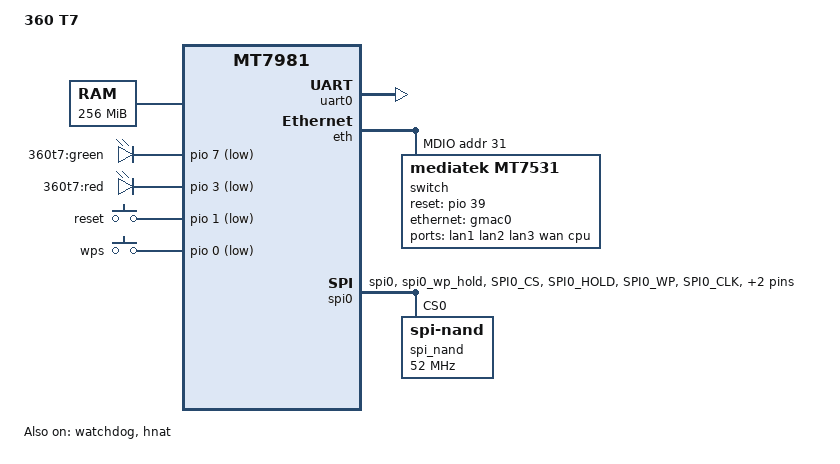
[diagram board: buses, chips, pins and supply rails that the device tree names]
/dts-v1/;
#include "mt7981.dtsi"

/ {
	model = "360 T7";
	compatible = "360,t7", "mediatek,mt7981";

	aliases {
		led-boot = &red_led;
		led-failsafe = &red_led;
		led-running = &green_led;
		led-upgrade = &green_led;
	};
	
 

	chosen {
		bootargs = "console=ttyS0,115200n1 loglevel=8  \
				earlycon=uart8250,mmio32,0x11002000";
	};

	memory {
		reg = <0 0x40000000 0 0x10000000>;
	};

	leds {
		compatible = "gpio-leds";

		green_led: green {
			label = "360t7:green";
			gpios = <&pio 7 GPIO_ACTIVE_LOW>;
		};

		red_led: red {
			label = "360t7:red";
			gpios = <&pio 3 GPIO_ACTIVE_LOW>;
		};
	};

	gpio-keys {
		compatible = "gpio-keys";
			reset {
				label = "reset";
				linux,code = <KEY_RESTART>;
				gpios = <&pio 1 GPIO_ACTIVE_LOW>;
			};

			wps {
				label = "wps";
				linux,code = <KEY_WPS_BUTTON>;
				gpios = <&pio 0 GPIO_ACTIVE_LOW>;
			};
	};

};

&uart0 {
	status = "okay";
};

&watchdog {
	status = "okay";
};


&eth {
        status = "okay";

        gmac0: mac@0 {
                compatible = "mediatek,eth-mac";
                reg = <0>;
                phy-mode = "2500base-x";

                fixed-link {
                        speed = <2500>;
                        full-duplex;
                        pause;
                };
        };

        gmac1: mac@1 {
		compatible = "mediatek,eth-mac";
		reg = <1>;
		phy-mode = "2500base-x";

		fixed-link {
			speed = <2500>;
			full-duplex;
			pause;
		};
	};

	mdio: mdio-bus {
		#address-cells = <1>;
		#size-cells = <0>;

		switch@0 {
			compatible = "mediatek,mt7531";
			reg = <31>;
			reset-gpios = <&pio 39 0>;

			ports {
				#address-cells = <1>;
				#size-cells = <0>;

				port@0 {
					reg = <0>;
					label = "lan1";
				};

				port@1 {
					reg = <1>;
					label = "lan2";
				};

				port@2 {
					reg = <2>;
					label = "lan3";
				};

				port@3 {
					reg = <3>;
					label = "wan";
				};

				port@6 {
					reg = <6>;
					label = "cpu";
					ethernet = <&gmac0>;
					phy-mode = "2500base-x";

					fixed-link {
						speed = <2500>;
						full-duplex;
						pause;
					};
				};
			};
		};
	};
};

&hnat {
	mtketh-wan = "eth1";
	mtketh-lan = "lan";
	mtketh-ppd = "eth1";
	mtketh-max-gmac = <2>;
	status = "okay";
};

&spi0 {
	pinctrl-names = "default";
	pinctrl-0 = <&spi0_flash_pins>;
	status = "okay";

	spi_nand: spi_nand@0 {
		#address-cells = <1>;
		#size-cells = <1>;
		compatible = "spi-nand";
		reg = <0>;
		spi-max-frequency = <52000000>;
		spi-tx-bus-width = <4>;
		spi-rx-bus-width = <4>;
		spi-cal-enable;
		spi-cal-mode = "read-data";
		spi-cal-datalen = <7>;
		spi-cal-data = /bits/ 8 <0x53 0x50 0x49 0x4E 0x41 0x4E 0x44>; /* 'SPINAND' */
		spi-cal-addrlen = <5>;
		spi-cal-addr = /bits/ 32 <0x0 0x0 0x0 0x0 0x0>;
	};
};

&pio {
	pwm0_pin: pwm0-pin-g0 {
		mux {
			function = "pwm";
			groups = "pwm0_0";
		};
	};

	pwm1_pin: pwm1-pin-g0 {
		mux {
			function = "pwm";
			groups = "pwm1_0";
		};
	};

	pwm2_pin: pwm2-pin {
		mux {
			function = "pwm";
			groups = "pwm2";
		};
	};

	spi0_flash_pins: spi0-pins {
		mux {
			function = "spi";
			groups = "spi0", "spi0_wp_hold";
		};

		conf-pu {
			pins = "SPI0_CS", "SPI0_HOLD", "SPI0_WP";
			drive-strength = <MTK_DRIVE_8mA>;
			bias-pull-up = <MTK_PUPD_SET_R1R0_11>;
		};

		conf-pd {
			pins = "SPI0_CLK", "SPI0_MOSI", "SPI0_MISO";
			drive-strength = <MTK_DRIVE_8mA>;
			bias-pull-down = <MTK_PUPD_SET_R1R0_11>;
		};
	};

	uart1_pins: uart1-pins-g1 {
		mux {
			function = "uart";
			groups = "uart1_1";
		};
	};

	uart2_pins: uart2-pins-g1 {
		mux {
			function = "uart";
			groups = "uart2_1";
		};
	};
};
